VERSION ""

NS_ :

BS_:

BU_: XXX DSU HCU EPS IPAS CGW BGM

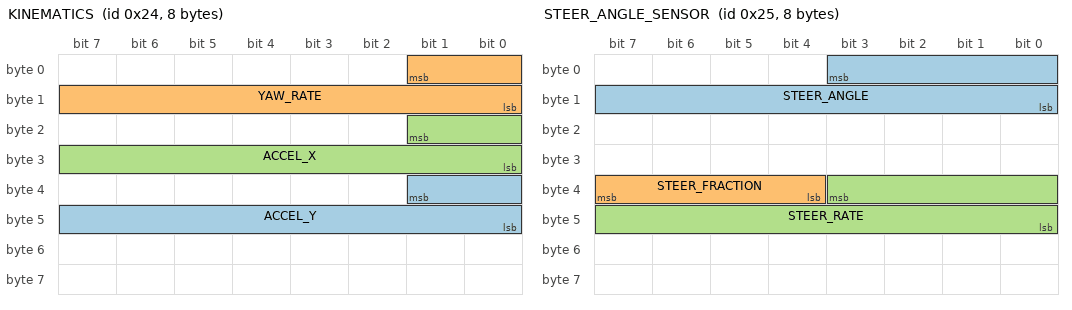
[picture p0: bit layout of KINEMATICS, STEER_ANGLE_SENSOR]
BO_ 36 KINEMATICS: 8 XXX
 SG_ ACCEL_Y : 33|10@0+ (0.03589,-18.375) [0|65535] "m/s^2" XXX
 SG_ YAW_RATE : 1|10@0+ (0.244,-125) [0|65535] "deg/s" XXX
 SG_ ACCEL_X : 17|10@0+ (0.03589,-18.375) [0|65535] "m/s^2" XXX

BO_ 37 STEER_ANGLE_SENSOR: 8 XXX
 SG_ STEER_ANGLE : 3|12@0- (1.5,0) [-500|500] "deg" XXX
 SG_ STEER_FRACTION : 39|4@0- (0.1,0) [-0.7|0.7] "deg" XXX
 SG_ STEER_RATE : 35|12@0- (1,0) [-2000|2000] "deg/s" XXX

BO_ 166 BRAKE: 8 XXX
 SG_ BRAKE_AMOUNT : 7|8@0+ (1,0) [0|255] "" XXX
 SG_ BRAKE_FORCE : 23|8@0+ (40,0) [0|10200] "N" XXX

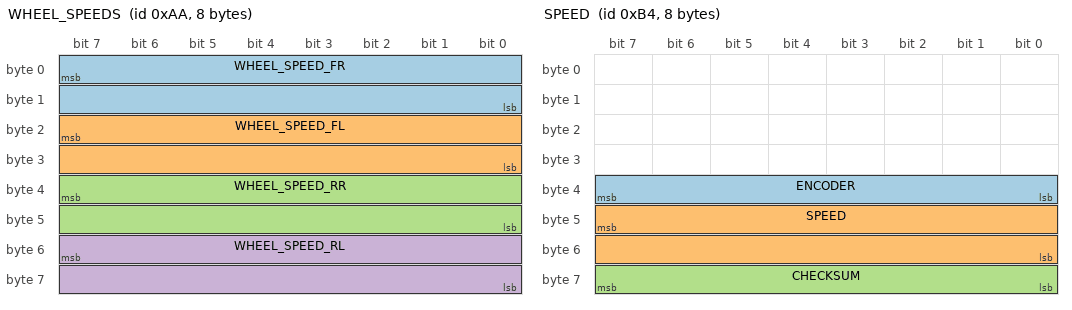
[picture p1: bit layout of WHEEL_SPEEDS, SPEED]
BO_ 170 WHEEL_SPEEDS: 8 XXX
 SG_ WHEEL_SPEED_FR : 7|16@0+ (0.01,-67.67) [0|250] "km/h" XXX
 SG_ WHEEL_SPEED_FL : 23|16@0+ (0.01,-67.67) [0|250] "km/h" XXX
 SG_ WHEEL_SPEED_RR : 39|16@0+ (0.01,-67.67) [0|250] "km/h" XXX
 SG_ WHEEL_SPEED_RL : 55|16@0+ (0.01,-67.67) [0|250] "km/h" XXX

BO_ 180 SPEED: 8 XXX
 SG_ ENCODER : 39|8@0+ (1,0) [0|255] "" XXX
 SG_ SPEED : 47|16@0+ (0.01,0) [0|250] "km/h" XXX
 SG_ CHECKSUM : 63|8@0+ (1,0) [0|255] "" XXX

BO_ 452 ENGINE_RPM: 8 CGW
 SG_ RPM : 7|16@0- (0.78125,0) [0|0] "rpm" XXX
 SG_ ENGINE_RUNNING : 27|1@0+ (1,0) [0|1] "" XXX

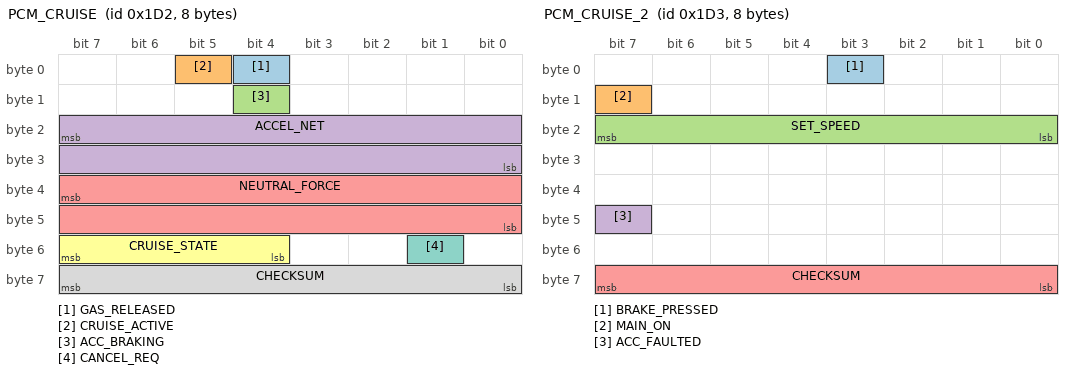
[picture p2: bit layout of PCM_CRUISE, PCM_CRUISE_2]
BO_ 466 PCM_CRUISE: 8 XXX
 SG_ GAS_RELEASED : 4|1@0+ (1,0) [0|1] "" XXX
 SG_ CRUISE_ACTIVE : 5|1@0+ (1,0) [0|1] "" XXX
 SG_ ACC_BRAKING : 12|1@0+ (1,0) [0|1] "" XXX
 SG_ ACCEL_NET : 23|16@0- (0.0009765625,0) [-20|20] "m/s^2" XXX
 SG_ NEUTRAL_FORCE : 39|16@0- (2,0) [-65536|65534] "N" XXX
 SG_ CRUISE_STATE : 55|4@0+ (1,0) [0|15] "" XXX
 SG_ CANCEL_REQ : 49|1@1+ (1,0) [0|1] "" XXX
 SG_ CHECKSUM : 63|8@0+ (1,0) [0|255] "" XXX

BO_ 467 PCM_CRUISE_2: 8 XXX
 SG_ BRAKE_PRESSED : 3|1@0+ (1,0) [0|1] "" XXX
 SG_ MAIN_ON : 15|1@0+ (1,0) [0|1] "" XXX
 SG_ SET_SPEED : 23|8@0+ (1,0) [0|255] "km/h" XXX
 SG_ ACC_FAULTED : 47|1@0+ (1,0) [0|1] "" XXX
 SG_ CHECKSUM : 63|8@0+ (1,0) [0|255] "" XXX

BO_ 548 BRAKE_MODULE: 8 XXX
 SG_ BRAKE_PRESSURE : 43|12@0+ (1,0) [0|4047] "" XXX
 SG_ BRAKE_PRESSED : 5|1@0+ (1,0) [0|1] "" XXX

BO_ 560 BRAKE_2: 7 XXX
 SG_ BRAKE_PRESSED : 26|1@0+ (1,0) [0|1] "" XXX

BO_ 581 GAS_PEDAL_HYBRID: 8 XXX
 SG_ GAS_PEDAL : 23|8@0+ (0.005,0) [0|1] "" XXX

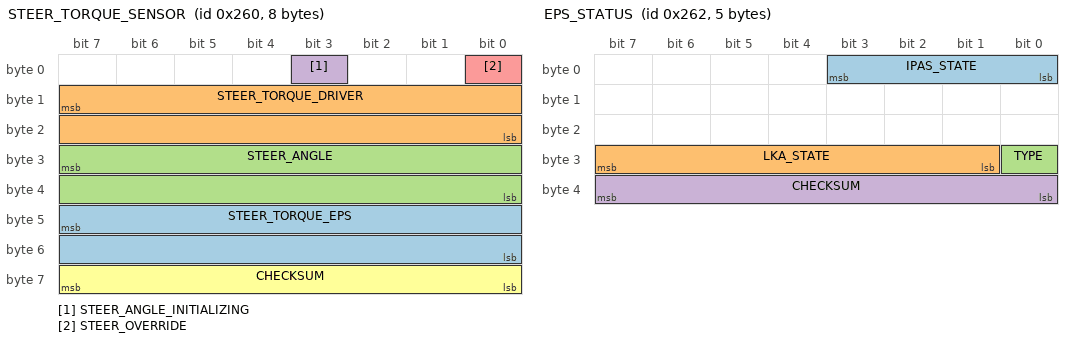
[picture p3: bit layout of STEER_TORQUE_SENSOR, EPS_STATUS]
BO_ 608 STEER_TORQUE_SENSOR: 8 XXX
 SG_ STEER_TORQUE_EPS : 47|16@0- (1,0) [-32768|32767] "" XXX
 SG_ STEER_TORQUE_DRIVER : 15|16@0- (1,0) [-32768|32767] "" XXX
 SG_ STEER_ANGLE : 31|16@0- (0.0573,0) [-500|500] "" XXX
 SG_ STEER_ANGLE_INITIALIZING : 3|1@0+ (1,0) [0|1] "" XXX
 SG_ STEER_OVERRIDE : 0|1@0+ (1,0) [0|1] "" XXX
 SG_ CHECKSUM : 63|8@0+ (1,0) [0|255] "" XXX

BO_ 610 EPS_STATUS: 5 EPS
 SG_ IPAS_STATE : 3|4@0+ (1,0) [0|15] "" XXX
 SG_ LKA_STATE : 31|7@0+ (1,0) [0|127] "" XXX
 SG_ TYPE : 24|1@0+ (1,0) [0|1] "" XXX
 SG_ CHECKSUM : 39|8@0+ (1,0) [0|255] "" XXX

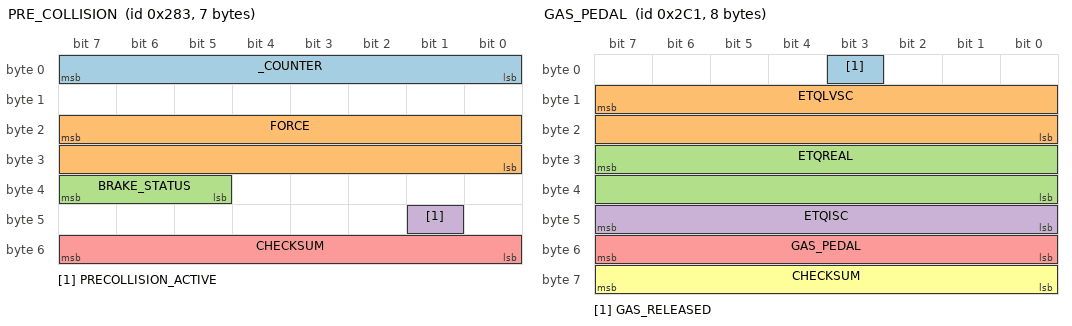
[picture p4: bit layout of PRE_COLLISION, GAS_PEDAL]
BO_ 643 PRE_COLLISION: 7 DSU
 SG_ _COUNTER : 7|8@0+ (1,0) [0|255] "" XXX
 SG_ FORCE : 23|16@0- (2,0) [0|255] "N" XXX
 SG_ BRAKE_STATUS : 39|3@0+ (1,0) [0|255] "" XXX
 SG_ PRECOLLISION_ACTIVE : 41|1@0+ (1,0) [0|255] "" XXX
 SG_ CHECKSUM : 55|8@0+ (1,0) [0|255] "" XXX

BO_ 705 GAS_PEDAL: 8 XXX
 SG_ GAS_RELEASED : 3|1@0+ (1,0) [0|1] "" XXX
 SG_ ETQLVSC : 15|16@0- (0.03125,0) [0|0] "Nm" XXX
 SG_ ETQREAL : 31|16@0- (0.03125,0) [0|0] "Nm" XXX
 SG_ ETQISC : 47|8@0+ (1,-192) [0|0] "Nm" XXX
 SG_ GAS_PEDAL : 55|8@0+ (0.5,0) [0|0] "%" XXX
 SG_ CHECKSUM : 63|8@0+ (1,0) [0|0] "" XXX

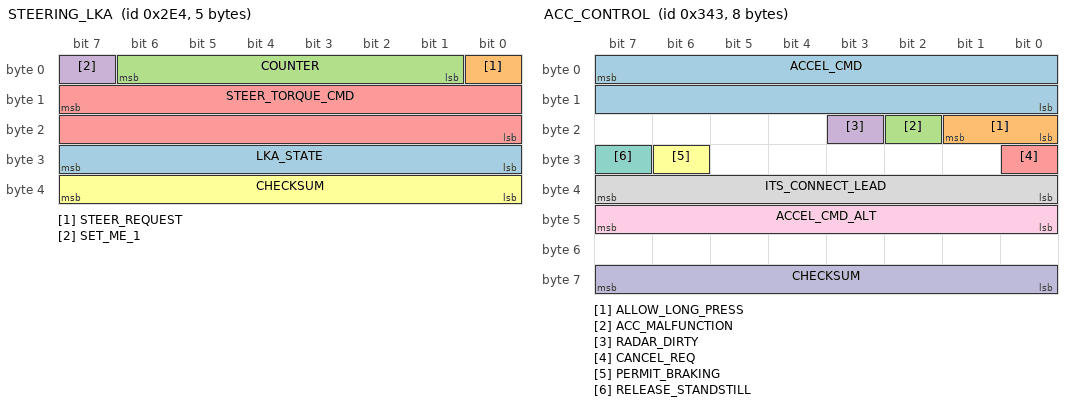
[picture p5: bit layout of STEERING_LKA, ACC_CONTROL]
BO_ 740 STEERING_LKA: 5 XXX
 SG_ LKA_STATE : 31|8@0+ (1,0) [0|255] "" XXX
 SG_ STEER_REQUEST : 0|1@0+ (1,0) [0|1] "" XXX
 SG_ COUNTER : 6|6@0+ (1,0) [0|63] "" XXX
 SG_ SET_ME_1 : 7|1@0+ (1,0) [0|1] "" XXX
 SG_ STEER_TORQUE_CMD : 15|16@0- (1,0) [-1500|1500] "" XXX
 SG_ CHECKSUM : 39|8@0+ (1,0) [0|255] "" XXX

BO_ 835 ACC_CONTROL: 8 DSU
 SG_ ACCEL_CMD : 7|16@0- (0.001,0) [-20|20] "m/s^2" HCU
 SG_ ALLOW_LONG_PRESS : 17|2@0+ (1,0) [0|2] "" XXX
 SG_ ACC_MALFUNCTION : 18|1@0+ (1,0) [0|0] "" XXX
 SG_ RADAR_DIRTY : 19|1@0+ (1,0) [0|1] "" XXX
 SG_ CANCEL_REQ : 24|1@0+ (1,0) [0|1] "" HCU
 SG_ PERMIT_BRAKING : 30|1@0+ (1,0) [0|1] "" HCU
 SG_ RELEASE_STANDSTILL : 31|1@0+ (1,0) [0|1] "" HCU
 SG_ ITS_CONNECT_LEAD : 39|8@0+ (1,0) [0|1] "" XXX
 SG_ ACCEL_CMD_ALT : 47|8@0- (0.05,0) [0|0] "m/s^2" XXX
 SG_ CHECKSUM : 63|8@0+ (1,0) [0|255] "" XXX

BO_ 956 GEAR_PACKET: 8 XXX
 SG_ GEAR : 13|6@0+ (1,0) [0|63] "" XXX
 SG_ DRIVE_ENGAGED : 47|1@0+ (1,0) [0|1] "" XXX

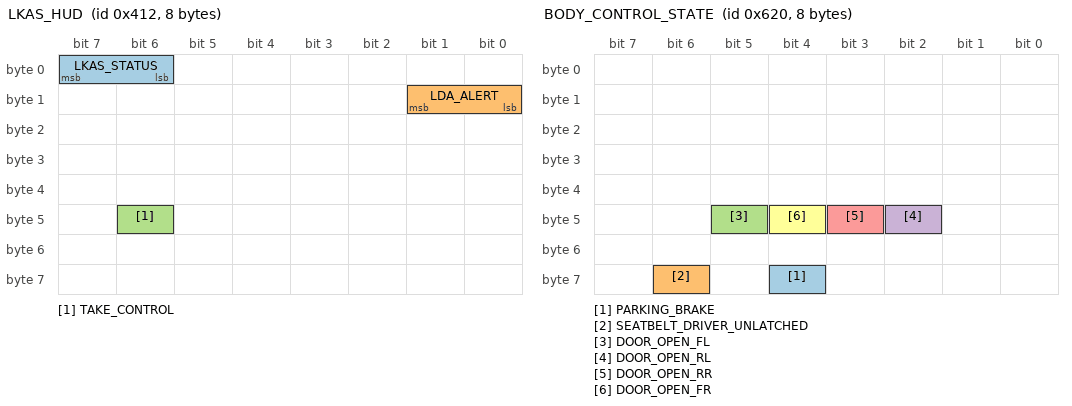
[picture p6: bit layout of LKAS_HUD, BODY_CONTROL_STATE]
BO_ 1042 LKAS_HUD: 8 DSU
 SG_ LKAS_STATUS : 7|2@0+ (1,0) [0|3] "" XXX
 SG_ LDA_ALERT : 9|2@0+ (1,0) [0|3] "" XXX
 SG_ TAKE_CONTROL : 46|1@0+ (1,0) [0|1] "" XXX

BO_ 1178 BRAKE_RELATED: 8 XXX
 SG_ BRAKE_PRESSED : 48|1@0+ (1,0) [0|1] "" XXX

BO_ 1556 BLINKERS_STATE: 8 XXX
 SG_ HAZARD_LIGHT : 27|1@0+ (1,0) [0|1] "" XXX
 SG_ TURN_SIGNALS : 29|2@0+ (1,0) [0|3] "" XXX

BO_ 1568 BODY_CONTROL_STATE: 8 XXX
 SG_ PARKING_BRAKE : 60|1@0+ (1,0) [0|1] "" XXX
 SG_ SEATBELT_DRIVER_UNLATCHED : 62|1@0+ (1,0) [0|1] "" XXX
 SG_ DOOR_OPEN_FL : 45|1@0+ (1,0) [0|1] "" XXX
 SG_ DOOR_OPEN_RL : 42|1@0+ (1,0) [0|1] "" XXX
 SG_ DOOR_OPEN_RR : 43|1@0+ (1,0) [0|1] "" XXX
 SG_ DOOR_OPEN_FR : 44|1@0+ (1,0) [0|1] "" XXX

CM_ SG_ 37 STEER_ANGLE "steering wheel angle in degrees";
CM_ SG_ 466 CRUISE_STATE "Active state is 8, standstill is 7, off is 0";
CM_ SG_ 608 STEER_TORQUE_DRIVER "driver torque";
CM_ SG_ 608 STEER_OVERRIDE "set when driver torque exceeds a certain value";
CM_ SG_ 740 STEER_TORQUE_CMD "torque command: positive=right, negative=left";
CM_ SG_ 835 PERMIT_BRAKING "set to 1 to allow braking from ACC command";
CM_ SG_ 835 RELEASE_STANDSTILL "set to 1 to release from standstill";
CM_ SG_ 835 ALLOW_LONG_PRESS "set to 2 to enable long press speed increment";

VAL_ 466 CRUISE_STATE 11 "timer_3sec" 10 "adaptive_click_down" 9 "adaptive_click_up" 8 "adaptive_engaged" 7 "standstill" 1 "non_adaptive_engaged" 0 "off";
VAL_ 610 IPAS_STATE 5 "override" 3 "enabled" 1 "disabled";
VAL_ 610 LKA_STATE 25 "temporary_fault" 9 "temporary_fault2" 5 "active" 1 "standby";
